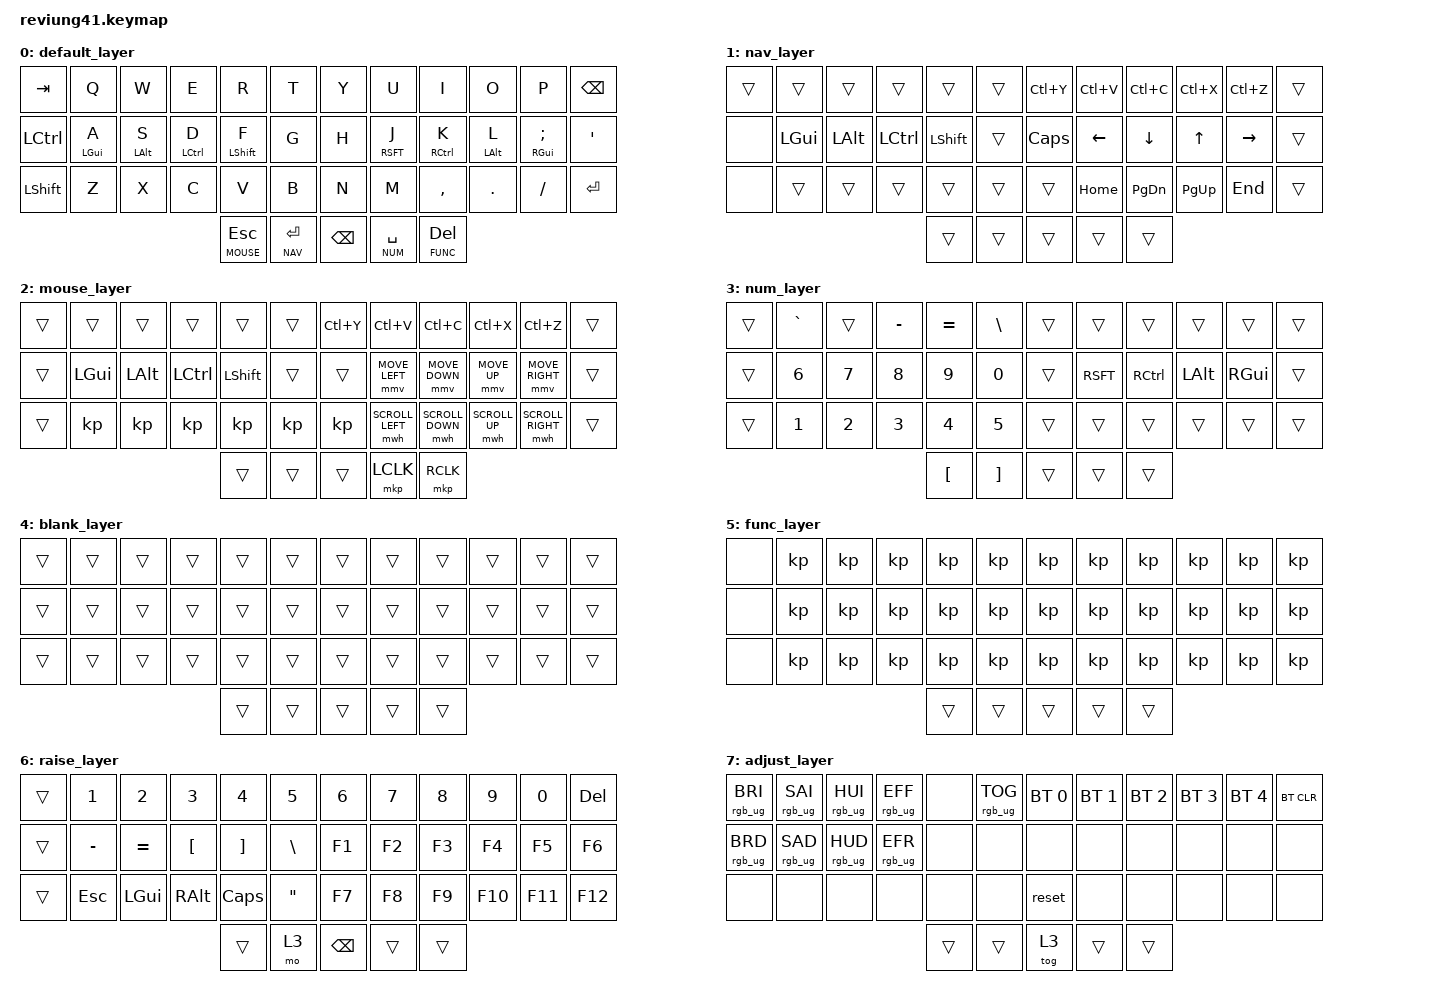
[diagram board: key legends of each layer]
/*
 * Copyright (c) 2020 The ZMK Contributors
 *
 * SPDX-License-Identifier: MIT
 */

#include <behaviors.dtsi>
#include <dt-bindings/zmk/keys.h>
#include <dt-bindings/zmk/bt.h>
#include <dt-bindings/zmk/rgb.h>
#include <dt-bindings/zmk/mouse.h>
#include <mousekeyspr.h>

#define DEFAULT 0
#define BASE  0
#define NAV   1
#define MOUSE 2
#define NUM   3

/ {
        keymap {
                compatible = "zmk,keymap";

                default_layer {
// -------------------------------------------------------------------------------------
// |  TAB |  Q    |  W    |  E    |  R    |  T  |   |  Y    |  U    |  I    |  O    |  P    |   BKSP    |
// | CTRL | GUI/A | ALT/S | CTL/D | SFT/F |  G  |   |  H    | SFT/J | CTL/K | ALT/L | GUI/; |    '      |
// | SHFT |  Z    |  X    |  C    |  V    |  B  |   |  N    |  M    |  ,    |  .    |  /    |   RET     |
//                         | MOUSE/ESC | NAV/RET | BKSP | NUM/SPC  | FUNC/DEL |
                        bindings = <
   &kp TAB   &kp Q      &kp W      &kp E       &kp R       &kp T              &kp Y &kp U       &kp I          &kp O       &kp P         &kp BSPC
   &kp LCTRL &mt LGUI A &mt LALT S &mt LCTRL D &mt LSHFT F &kp G              &kp H &mt RSFT J  &mt RCTRL K    &mt LALT L  &mt RGUI SEMI &kp SQT
   &kp LSHFT &kp Z      &kp X      &kp C       &kp V       &kp B              &kp N &kp M       &kp COMMA      &kp DOT     &kp FSLH      &kp RET
                                             &lt MOUSE ESC &lt NAV RET  &kp BSPC   &lt NUM SPC &lt FUNC DEL
                        >;
                };

                nav_layer {
// ----------------------------------------------------------------------------------
// |    |      |      |      |      |     |   | AGAIN | PASTE | COPY | CUT  | UNDO |   |
// |    | LGUI | LALT | LCTL | LSFT |     |   | CAPS  | LEFT  | DOWN | UP   | RIGHT|   |
// |    |      |      |      |      |     |   |       | HOME  | PGDN | PGUP | END  |   |
//                       |     |     |     |     |     |
                        bindings = <
   &trans &trans    &trans   &trans    &trans    &trans         &kp LC(Y) &kp LC(V) &kp LC(C) &kp LC(X) &kp LC(Z) &trans
   &      &kp LGUI  &kp LALT &kp LCTRL &kp LSHFT &trans         &kp CAPS  &kp LEFT  &kp DOWN  &kp UP    &kp RIGHT &trans
   &      &trans    &trans   &trans    &trans    &trans         &trans    &kp HOME  &kp PG_DN &kp PG_UP &kp END   &trans
                                 &trans      &trans       &trans        &trans     &trans
                        >;
                };

                mouse_layer {
// ----------------------------------------------------------------------------------
// |    |      |      |      |      |     |   | AGAIN | PASTE | COPY | CUT  | UNDO |   |
// |    | LGUI | LALT | LCTL | LSFT |     |   |       | MS_L  | MS_D | MS_U | MS_R |   |
// |    |      |      |      |      |     |   |       |  sc_L | SC_D | SC_U | SC_R |   |
//                       |     |     |     | MS_1 | MS_2 |
                        bindings = <
   &trans &trans    &trans   &trans    &trans    &trans         &kp LC(Y) &kp LC(V) &kp LC(C) &kp LC(X) &kp LC(Z) &trans
   &trans &kp LGUI  &kp LALT &kp LCTRL &kp LSHFT &trans         &trans    &mmv MOVE_LEFT  &mmv MOVE_DOWN &mmv MOVE_UP&mmv MOVE_RIGHT &trans
   &trans &kp       &kp         &kp      &kp      &kp            &kp      &mwh SCROLL_LEFT &mwh SCROLL_DOWN  &mwh SCROLL_UP &mwh SCROLL_RIGHT &trans
                                 &trans      &trans       &trans        &mkp LCLK &mkp RCLK
                        >;
                };


                num_layer {
// ----------------------------------------------------------------------------------
// |    |  `  |     |  -  |  =  |  \  |   |     |      |      |      |      |       |
// |    |  6  |  7  |  8  |  9  |  0  |   |     | RSFT | RCTL | LALT | RGUI |       |
// |    |  1  |  2  |  3  |  4  |  5  |   |     |      |      |      |      |       |
//                       |     |     |     |     |     |
                        bindings = <
   &trans &kp GRAVE &trans     &kp MINUS &kp EQUAL &kp BSLH      &trans    &trans   &trans    &trans    &trans    &trans
   &trans &kp N6    &kp N7      &kp N8   &kp N9   &kp N0         &trans    &kp RSFT &kp RCTRL  &kp LALT &kp RGUI  &trans
   &trans &kp N1    &kp N2      &kp N3   &kp N4   &kp N5         &trans    &trans   &trans    &trans    &trans    &trans
                                 &kp LBKT      &kp RBKT       &trans        &trans     &trans
                        >;
                };


                blank_layer {
// ----------------------------------------------------------------------------------
// |    |     |     |     |     |     |   |     |     |     |     |     |           |
// |    |     |     |     |     |     |   |     |     |     |     |     |           |
// |    |     |     |     |     |     |   |     |     |     |     |     |           |
//                       |     |     |     |     |     |
                        bindings = <
   &trans      &trans    &trans      &trans   &trans   &trans         &trans    &trans   &trans    &trans    &trans    &trans
   &trans      &trans    &trans      &trans   &trans   &trans         &trans    &trans   &trans    &trans    &trans    &trans
   &trans      &trans    &trans      &trans   &trans   &trans         &trans    &trans   &trans    &trans    &trans    &trans
                                 &trans      &trans    &trans      &trans   &trans 
                        >;
                };

                func_layer {
// ----------------------------------------------------------------------------------
// |    |     |     |     |     |     |   |     |     |     |     |     |           |
// |    |     |     |     |     |     |   |     |     |     |     |     |           |
// |    |     |     |     |     |     |   |     |     |     |     |     |           |
//                       |     |     |     |     |     |
                        bindings = <
   &      &kp       &kp         &kp      &kp      &kp            &kp       &kp      &kp       &kp       &kp       &kp   
   &      &kp       &kp         &kp      &kp      &kp            &kp       &kp      &kp       &kp       &kp       &kp   
   &      &kp       &kp         &kp      &kp      &kp            &kp       &kp      &kp       &kp       &kp       &kp   
                                 &trans      &trans       &trans        &trans     &trans
                        >;
                };

                raise_layer {
// -----------------------------------------------------------------------------------------
// |    |  1  |  2  |  3  |  4  |  5  |   |  6  |  7  |  8  |  9  |  0  | DEL |
// |    |  -  |  =  |  [  |  ]  |  \  |   | F1  | F2  | F3  | F4  | F5  | F6  |
// |    | ESC | GUI | ALT | CAPS|  "  |   | F7  | F8  | F9  | F10 | F11 | F12 |
//                       |     | ADJ | BKSP |    |     |
                        bindings = <
   &trans &kp N1    &kp N2    &kp N3    &kp N4    &kp N5        &kp N6    &kp N7    &kp N8    &kp N9    &kp N0    &kp DEL
   &trans &kp MINUS &kp EQUAL &kp LBKT  &kp RBKT  &kp BSLH      &kp F1    &kp F2    &kp F3    &kp F4    &kp F5    &kp F6
   &trans &kp ESC   &kp LGUI  &kp RALT  &kp CLCK  &kp DQT       &kp F7    &kp F8    &kp F9    &kp F10   &kp F11   &kp F12
                                &trans      &mo 3       &kp BSPC        &trans      &trans
                        >;
                };

                adjust_layer {
// -----------------------------------------------------------------------------------------
// | RGB BRI+ | RGB SAT+ | RGB HUE+ | RGB ANI+ |    | RGB TOG |   |  BT1  | BT2 | BT3 | BT4 | BT5 | BT CLR |
// | RGB BRI- | RGB SAT- | RGB HUE- | RGB ANI- |    |         |   |       |     |     |     |     |        |
// |          |          |          |          |    |         |   | RESET |     |     |     |     |        |
//                                              |     |     |     |     |     |
                        bindings = <
   &rgb_ug RGB_BRI &rgb_ug RGB_SAI &rgb_ug RGB_HUI &rgb_ug RGB_EFF &none &rgb_ug RGB_TOG    &bt BT_SEL 0 &bt BT_SEL 1 &bt BT_SEL 2 &bt BT_SEL 3 &bt BT_SEL 4 &bt BT_CLR
   &rgb_ug RGB_BRD &rgb_ug RGB_SAD &rgb_ug RGB_HUD &rgb_ug RGB_EFR &none &none              &none        &none        &none        &none        &none        &none
   &none           &none           &none           &none           &none &none              &reset       &none        &none        &none        &none        &none
                                                             &trans      &trans       &tog 3        &trans      &trans
                        >;
                };
        };
};
